AUTOSAR XML (schema 314)
package /ComponentType
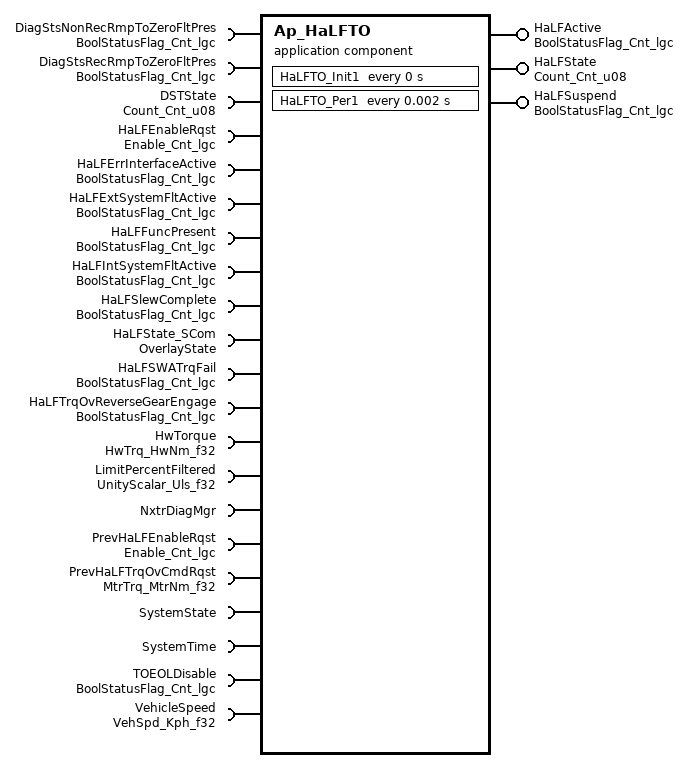
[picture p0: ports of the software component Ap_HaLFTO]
  application software component type Ap_HaLFTO
    provide port HaLFActive: unqueued-sender-com-spec{data-element=Cnt_lgc, can-invalidate=false, init-value=D_FALSE_CNT_LGC}, provided-interface=BoolStatusFlag_Cnt_lgc
    provide port HaLFState: unqueued-sender-com-spec{data-element=Cnt_u08, can-invalidate=false, init-value=D_ZERO_CNT_U8}, provided-interface=Count_Cnt_u08
    provide port HaLFSuspend: unqueued-sender-com-spec{data-element=Cnt_lgc, can-invalidate=false, init-value=D_FALSE_CNT_LGC}, provided-interface=BoolStatusFlag_Cnt_lgc
    21 x require port:
      DiagStsNonRecRmpToZeroFltPres: unqueued-receiver-com-spec{data-element=Cnt_lgc, init-value=D_FALSE_CNT_LGC}, required-interface=BoolStatusFlag_Cnt_lgc
      DiagStsRecRmpToZeroFltPres: unqueued-receiver-com-spec{data-element=Cnt_lgc, init-value=D_FALSE_CNT_LGC}, required-interface=BoolStatusFlag_Cnt_lgc
      DSTState: unqueued-receiver-com-spec{data-element=Cnt_u08, init-value=D_ZERO_CNT_U8}, required-interface=Count_Cnt_u08
      HaLFEnableRqst: unqueued-receiver-com-spec{data-element=Cnt_lgc, init-value=D_FALSE_CNT_LGC}, required-interface=Enable_Cnt_lgc
      HaLFErrInterfaceActive: unqueued-receiver-com-spec{data-element=Cnt_lgc, init-value=D_FALSE_CNT_LGC}, required-interface=BoolStatusFlag_Cnt_lgc
      HaLFExtSystemFltActive: unqueued-receiver-com-spec{data-element=Cnt_lgc, init-value=D_FALSE_CNT_LGC}, required-interface=BoolStatusFlag_Cnt_lgc
      HaLFFuncPresent: unqueued-receiver-com-spec{data-element=Cnt_lgc, init-value=D_FALSE_CNT_LGC}, required-interface=BoolStatusFlag_Cnt_lgc
      HaLFIntSystemFltActive: unqueued-receiver-com-spec{data-element=Cnt_lgc, init-value=D_FALSE_CNT_LGC}, required-interface=BoolStatusFlag_Cnt_lgc
      HaLFSlewComplete: unqueued-receiver-com-spec{data-element=Cnt_lgc, init-value=D_FALSE_CNT_LGC}, required-interface=BoolStatusFlag_Cnt_lgc
      HaLFState_SCom: client-com-spec=Transition, required-interface=OverlayState
      HaLFSWATrqFail: unqueued-receiver-com-spec{data-element=Cnt_lgc, init-value=D_FALSE_CNT_LGC}, required-interface=BoolStatusFlag_Cnt_lgc
      HaLFTrqOvReverseGearEngage: unqueued-receiver-com-spec{data-element=Cnt_lgc, init-value=D_FALSE_CNT_LGC}, required-interface=BoolStatusFlag_Cnt_lgc
      HwTorque: unqueued-receiver-com-spec{data-element=HwNm_f32, init-value=D_ZERO_ULS_F32}, required-interface=HwTrq_HwNm_f32
      LimitPercentFiltered: unqueued-receiver-com-spec{data-element=Uls_f32, init-value=D_ZERO_ULS_F32}, required-interface=UnityScalar_Uls_f32
      NxtrDiagMgr: required-com-specs=[GetNTCActive, GetNTCFailed, GetNTCStatus, SetNTCStatus], required-interface=NxtrDiagMgr
      PrevHaLFEnableRqst: unqueued-receiver-com-spec{data-element=Cnt_lgc, init-value=D_FALSE_CNT_LGC}, required-interface=Enable_Cnt_lgc
      PrevHaLFTrqOvCmdRqst: unqueued-receiver-com-spec{data-element=MtrNm_f32, init-value=D_ZERO_ULS_F32}, required-interface=MtrTrq_MtrNm_f32
      SystemState: required-interface=SystemState
      SystemTime: required-interface=SystemTime
        required-com-specs:
          DtrmnElapsedTime_mS_u16
          DtrmnElapsedTime_mS_u32
          DtrmnElapsedTime_uS_u16
          DtrmnElapsedTime_uS_u32
          GetSystemTime_mS_u32
          GetSystemTime_uS_u32
      TOEOLDisable: unqueued-receiver-com-spec{data-element=Cnt_lgc, init-value=D_FALSE_CNT_LGC}, required-interface=BoolStatusFlag_Cnt_lgc
      VehicleSpeed: unqueued-receiver-com-spec{data-element=Kph_f32, init-value=D_ZERO_ULS_F32}, required-interface=VehSpd_Kph_f32
  internal behavior Ap_HaLFTO_InternalBehavior: component=Ap_HaLFTO
    timing event HaLFTO_Init1_InitEvent: start-on-event=HaLFTO_Init1, period=0
    timing event TMT_HaLFTO_Per1: start-on-event=HaLFTO_Per1, period=0.002
    port-api-options:
      enable-take-address=false, indirect-api=false, port=DiagStsNonRecRmpToZeroFltPres
      enable-take-address=false, indirect-api=false, port=DiagStsRecRmpToZeroFltPres
      enable-take-address=false, indirect-api=false, port=DSTState
      enable-take-address=false, indirect-api=false, port=HaLFActive
      enable-take-address=false, indirect-api=false, port=HaLFEnableRqst
      enable-take-address=false, indirect-api=false, port=HaLFErrInterfaceActive
      enable-take-address=false, indirect-api=false, port=HaLFExtSystemFltActive
      enable-take-address=false, indirect-api=false, port=HaLFFuncPresent
      enable-take-address=false, indirect-api=false, port=HaLFIntSystemFltActive
      enable-take-address=false, indirect-api=false, port=HaLFSlewComplete
      enable-take-address=false, indirect-api=false, port=HaLFState
      enable-take-address=false, indirect-api=false, port=HaLFState_SCom
      enable-take-address=false, indirect-api=false, port=HaLFSuspend
      enable-take-address=false, indirect-api=false, port=HaLFSWATrqFail
      enable-take-address=false, indirect-api=false, port=HaLFTrqOvReverseGearEngage
      enable-take-address=false, indirect-api=false, port=HwTorque
      enable-take-address=false, indirect-api=false, port=LimitPercentFiltered
      enable-take-address=false, indirect-api=false, port=NxtrDiagMgr
      enable-take-address=false, indirect-api=false, port=PrevHaLFEnableRqst
      enable-take-address=false, indirect-api=false, port=PrevHaLFTrqOvCmdRqst
      enable-take-address=false, indirect-api=false, port=SystemState
      enable-take-address=false, indirect-api=false, port=SystemTime
      enable-take-address=false, indirect-api=false, port=TOEOLDisable
      enable-take-address=false, indirect-api=false, port=VehicleSpeed
    runnable HaLFTO_Init1
      sync call SC_HaLFState_SCom_Transition: operation=HaLFState_SCom.Transition, timeout=0
      sync call SC_SystemTime_GetSystemTime_mS_u32: operation=SystemTime.GetSystemTime_mS_u32, timeout=0
    runnable HaLFTO_Per1
      17 x data read access:
        READ_DiagStsNonRecRmpToZeroFltPres_Cnt_lgc: data-element=DiagStsNonRecRmpToZeroFltPres.Cnt_lgc
        READ_DiagStsRecRmpToZeroFltPres_Cnt_lgc: data-element=DiagStsRecRmpToZeroFltPres.Cnt_lgc
        READ_DSTState_Cnt_u08: data-element=DSTState.Cnt_u08
        READ_HaLFEnableRqst_Cnt_lgc: data-element=HaLFEnableRqst.Cnt_lgc
        READ_HaLFErrInterfaceActive_Cnt_lgc: data-element=HaLFErrInterfaceActive.Cnt_lgc
        READ_HaLFExtSystemFltActive_Cnt_lgc: data-element=HaLFExtSystemFltActive.Cnt_lgc
        READ_HaLFFuncPresent_Cnt_lgc: data-element=HaLFFuncPresent.Cnt_lgc
        READ_HaLFIntSystemFltActive_Cnt_lgc: data-element=HaLFIntSystemFltActive.Cnt_lgc
        READ_HaLFSlewComplete_Cnt_lgc: data-element=HaLFSlewComplete.Cnt_lgc
        READ_HaLFSWATrqFail_Cnt_lgc: data-element=HaLFSWATrqFail.Cnt_lgc
        READ_HaLFTrqOvReverseGearEngage_Cnt_lgc: data-element=HaLFTrqOvReverseGearEngage.Cnt_lgc
        READ_HwTorque_HwNm_f32: data-element=HwTorque.HwNm_f32
        READ_LimitPercentFiltered_Uls_f32: data-element=LimitPercentFiltered.Uls_f32
        READ_PrevHaLFEnableRqst_Cnt_lgc: data-element=PrevHaLFEnableRqst.Cnt_lgc
        READ_PrevHaLFTrqOvCmdRqst_MtrNm_f32: data-element=PrevHaLFTrqOvCmdRqst.MtrNm_f32
        READ_TOEOLDisable_Cnt_lgc: data-element=TOEOLDisable.Cnt_lgc
        READ_VehicleSpeed_Kph_f32: data-element=VehicleSpeed.Kph_f32
      data write access WRITE_HaLFActive_Cnt_lgc: data-element=HaLFActive.Cnt_lgc
      data write access WRITE_HaLFState_Cnt_u08: data-element=HaLFState.Cnt_u08
      data write access WRITE_HaLFSuspend_Cnt_lgc: data-element=HaLFSuspend.Cnt_lgc
      5 x sync call, all with timeout=0:
        SC_HaLFState_SCom_Transition: operation=HaLFState_SCom.Transition
        SC_NxtrDiagMgr_GetNTCFailed: operation=NxtrDiagMgr.GetNTCFailed
        SC_NxtrDiagMgr_SetNTCStatus: operation=NxtrDiagMgr.SetNTCStatus
        SC_SystemTime_DtrmnElapsedTime_mS_u16: operation=SystemTime.DtrmnElapsedTime_mS_u16
        SC_SystemTime_GetSystemTime_mS_u32: operation=SystemTime.GetSystemTime_mS_u32
  swc implementation Ap_HaLFTO_Implementation: behavior=Ap_HaLFTO_InternalBehavior
    code-descriptors:
      code Code: type=SRC
